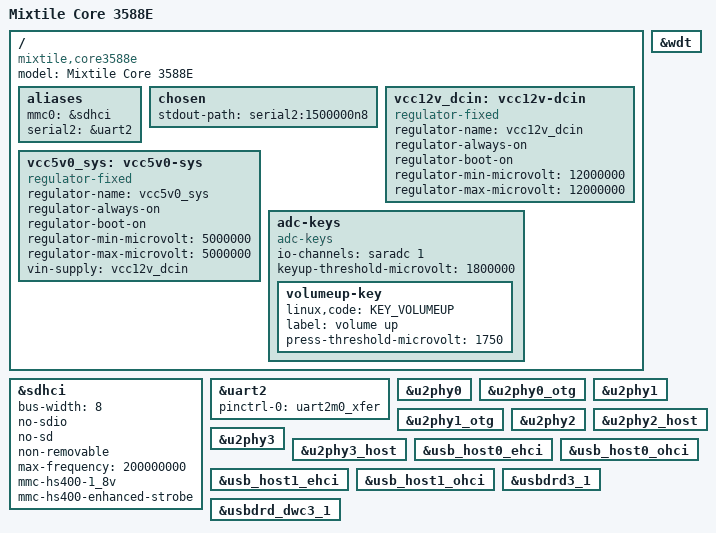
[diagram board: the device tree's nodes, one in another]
// SPDX-License-Identifier: (GPL-2.0+ OR MIT)
/*
 * Copyright (c) 2021 Rockchip Electronics Co., Ltd
 *
 */

/dts-v1/;
#include "rk3588.dtsi"
#include <dt-bindings/gpio/gpio.h>
#include <dt-bindings/input/input.h>
#include <dt-bindings/pinctrl/rockchip.h>
/* SDK common definitions; the board is kept in this single source file. */
#include "rk3588-evb-u-boot.dtsi"

/ {
	model = "Mixtile Core 3588E";
	compatible = "mixtile,core3588e", "rockchip,rk3588";

	aliases {
		mmc0 = &sdhci;
		serial2 = &uart2;
	};

	chosen {
		stdout-path = "serial2:1500000n8";
	};

	vcc12v_dcin: vcc12v-dcin {
		bootph-all;
		compatible = "regulator-fixed";
		regulator-name = "vcc12v_dcin";
		regulator-always-on;
		regulator-boot-on;
		regulator-min-microvolt = <12000000>;
		regulator-max-microvolt = <12000000>;
	};

	vcc5v0_sys: vcc5v0-sys {
		bootph-all;
		compatible = "regulator-fixed";
		regulator-name = "vcc5v0_sys";
		regulator-always-on;
		regulator-boot-on;
		regulator-min-microvolt = <5000000>;
		regulator-max-microvolt = <5000000>;
		vin-supply = <&vcc12v_dcin>;
	};

	adc-keys {
		compatible = "adc-keys";
		io-channels = <&saradc 1>;
		io-channel-names = "buttons";
		keyup-threshold-microvolt = <1800000>;
		bootph-all;
		status = "okay";

		volumeup-key {
			bootph-all;
			linux,code = <KEY_VOLUMEUP>;
			label = "volume up";
			press-threshold-microvolt = <1750>;
		};
	};
};

&sdhci {
	bus-width = <8>;
	no-sdio;
	no-sd;
	non-removable;
	max-frequency = <200000000>;
	mmc-hs400-1_8v;
	mmc-hs400-enhanced-strobe;
	status = "okay";
};

&uart2 {
	pinctrl-0 = <&uart2m0_xfer>;
	status = "okay";
};

&wdt {
	bootph-all;
};

&u2phy0 {
	status = "okay";
};

&u2phy0_otg {
	status = "okay";
};

&u2phy1 {
	status = "okay";
};

&u2phy1_otg {
	status = "okay";
};

&u2phy2 {
	status = "okay";
};

&u2phy2_host {
	status = "okay";
};

&u2phy3 {
	status = "okay";
};

&u2phy3_host {
	status = "okay";
};

&usb_host0_ehci {
	status = "okay";
};

&usb_host0_ohci {
	status = "okay";
};

&usb_host1_ehci {
	status = "okay";
};

&usb_host1_ohci {
	status = "okay";
};

&usbdrd3_1 {
	status = "okay";
};

&usbdrd_dwc3_1 {
	status = "okay";
};
